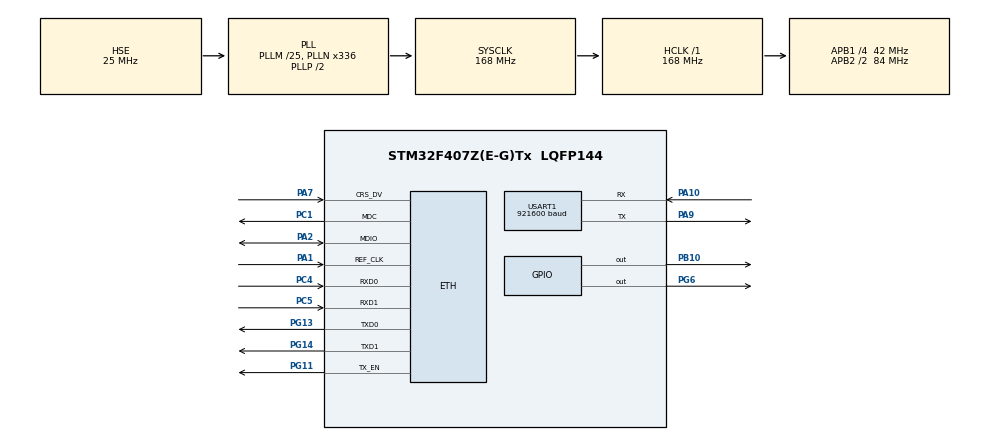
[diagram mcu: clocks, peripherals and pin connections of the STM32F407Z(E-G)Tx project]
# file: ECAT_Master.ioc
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Dma.Request0=USART1_RX
Dma.Request1=USART1_TX
Dma.USART1_RX.0.Direction=DMA_PERIPH_TO_MEMORY
Dma.USART1_RX.0.FIFOMode=DMA_FIFOMODE_DISABLE
Dma.USART1_RX.0.Instance=DMA2_Stream2
Dma.USART1_RX.0.MemDataAlignment=DMA_MDATAALIGN_BYTE
Dma.USART1_RX.0.MemInc=DMA_MINC_ENABLE
Dma.USART1_RX.0.Mode=DMA_CIRCULAR
Dma.USART1_RX.0.PeriphDataAlignment=DMA_PDATAALIGN_BYTE
Dma.USART1_RX.0.PeriphInc=DMA_PINC_DISABLE
Dma.USART1_RX.0.Priority=DMA_PRIORITY_LOW
Dma.USART1_TX.1.Direction=DMA_MEMORY_TO_PERIPH
Dma.USART1_TX.1.FIFOMode=DMA_FIFOMODE_DISABLE
Dma.USART1_TX.1.Instance=DMA2_Stream7
Dma.USART1_TX.1.MemDataAlignment=DMA_MDATAALIGN_BYTE
Dma.USART1_TX.1.MemInc=DMA_MINC_ENABLE
Dma.USART1_TX.1.Mode=DMA_NORMAL
Dma.USART1_TX.1.PeriphDataAlignment=DMA_PDATAALIGN_BYTE
Dma.USART1_TX.1.PeriphInc=DMA_PINC_DISABLE
Dma.USART1_TX.1.Priority=DMA_PRIORITY_LOW
ETH.MediaInterface=HAL_ETH_RMII_MODE
ETH.PHY_Name_RMII=LAN8742A_PHY_ADDRESS
Mcu.Family=STM32F4
Mcu.Name=STM32F407Z(E-G)Tx
Mcu.Package=LQFP144
NVIC.DMA2_Stream2_IRQn=true\:2\:0\:true\:false\:true\:false\:true\:true
NVIC.DMA2_Stream7_IRQn=true\:2\:0\:true\:false\:true\:false\:true\:true
NVIC.PriorityGroup=NVIC_PRIORITYGROUP_4
NVIC.USART1_IRQn=true\:0\:0\:false\:false\:true\:true\:true\:true
PA1.Mode=RMII
PA1.Signal=ETH_REF_CLK
PA10.Mode=Asynchronous
PA10.Signal=USART1_RX
PA13.Mode=Serial_Wire
PA13.Signal=SYS_JTMS-SWDIO
PA14.Mode=Serial_Wire
PA14.Signal=SYS_JTCK-SWCLK
PA2.Mode=RMII
PA2.Signal=ETH_MDIO
PA7.Mode=RMII
PA7.Signal=ETH_CRS_DV
PA9.Mode=Asynchronous
PA9.Signal=USART1_TX
PB10.Signal=GPIO_Output
PC1.Mode=RMII
PC1.Signal=ETH_MDC
PC4.Mode=RMII
PC4.Signal=ETH_RXD0
PC5.Mode=RMII
PC5.Signal=ETH_RXD1
PG11.Mode=RMII
PG11.Signal=ETH_TX_EN
PG13.Mode=RMII
PG13.Signal=ETH_TXD0
PG14.Mode=RMII
PG14.Signal=ETH_TXD1
PG6.Signal=GPIO_Output
PH0-OSC_IN.Mode=HSE-External-Oscillator
PH0-OSC_IN.Signal=RCC_OSC_IN
PH1-OSC_OUT.Mode=HSE-External-Oscillator
PH1-OSC_OUT.Signal=RCC_OSC_OUT
ProjectManager.HeapSize=0x200
ProjectManager.StackSize=0x400
ProjectManager.TargetToolchain=STM32CubeIDE
RCC.48MHZClocksFreq_Value=84000000
RCC.AHBFreq_Value=168000000
RCC.APB1CLKDivider=RCC_HCLK_DIV4
RCC.APB1Freq_Value=42000000
RCC.APB1TimFreq_Value=84000000
RCC.APB2CLKDivider=RCC_HCLK_DIV2
RCC.APB2Freq_Value=84000000
RCC.APB2TimFreq_Value=168000000
RCC.CortexFreq_Value=168000000
RCC.HCLKFreq_Value=168000000
RCC.HSE_VALUE=25000000
RCC.HSI_VALUE=16000000
RCC.LSE_VALUE=32768
RCC.PLLM=25
RCC.PLLN=336
RCC.PLLSourceVirtual=RCC_PLLSOURCE_HSE
RCC.SYSCLKFreq_VALUE=168000000
RCC.SYSCLKSource=RCC_SYSCLKSOURCE_PLLCLK
RCC.VCOOutputFreq_Value=336000000
TIM2.AutoReloadPreload=TIM_AUTORELOAD_PRELOAD_ENABLE
TIM2.Period=1000000
TIM2.Prescaler=84-1
TIM2.TIM_MasterOutputTrigger=TIM_TRGO_UPDATE
TIM2.TIM_MasterSlaveMode=TIM_MASTERSLAVEMODE_ENABLE
USART1.BaudRate=921600
USART1.VirtualMode=VM_ASYNC
VP_TIM2_VS_ClockSourceINT.Mode=Internal
VP_TIM5_VS_ClockSourceITR.Mode=TriggerSource_ITR0
VP_TIM5_VS_ControllerModeClock.Mode=Clock Mode
board=custom

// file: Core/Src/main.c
/* USER CODE BEGIN Header */
/**
  ******************************************************************************
  * @file           : main.c
  * @brief          : Main program body
  ******************************************************************************
  * @attention
  *
  * Copyright (c) 2023 STMicroelectronics.
  * All rights reserved.
  *
  * This software is licensed under terms that can be found in the LICENSE file
  * in the root directory of this software component.
  * If no LICENSE file comes with this software, it is provided AS-IS.
  *
  ******************************************************************************
  */
/* USER CODE END Header */
#include "main.h"
#include "dma.h"
#include "eth.h"
#include "tim.h"
#include "usart.h"
#include "gpio.h"

/* USER CODE BEGIN PTD */
void SystemClock_PreConfig(void);
/* USER CODE END PTD */

void SystemClock_Config(void);

int main(void)
{

  /* MCU Configuration--------------------------------------------------------*/

  /* Reset of all peripherals, Initializes the Flash interface and the Systick. */
  HAL_Init();

  /* USER CODE BEGIN Init */
    SystemClock_PreConfig();
  /* USER CODE END Init */

  /* Configure the system clock */
  SystemClock_Config();

  /* Initialize all configured peripherals */
  MX_GPIO_Init();
    MX_DMA_Init();
  MX_USART1_UART_Init();

  MX_ETH_Init();
  MX_TIM2_Init();
  MX_TIM5_Init();

  /* Infinite loop */
  /* USER CODE BEGIN WHILE */
  mymain();
  while (1)
  {
    /* USER CODE END WHILE */

  }
}

void SystemClock_Config(void)
{
  RCC_OscInitTypeDef RCC_OscInitStruct = {0};
  RCC_ClkInitTypeDef RCC_ClkInitStruct = {0};

  /** Configure the main internal regulator output voltage
  */
  __HAL_RCC_PWR_CLK_ENABLE();
  __HAL_PWR_VOLTAGESCALING_CONFIG(PWR_REGULATOR_VOLTAGE_SCALE1);

  /** Initializes the RCC Oscillators according to the specified parameters
  * in the RCC_OscInitTypeDef structure.
  */
  RCC_OscInitStruct.OscillatorType = RCC_OSCILLATORTYPE_HSE;
  RCC_OscInitStruct.HSEState = RCC_HSE_ON;
  RCC_OscInitStruct.PLL.PLLState = RCC_PLL_ON;
  RCC_OscInitStruct.PLL.PLLSource = RCC_PLLSOURCE_HSE;
  RCC_OscInitStruct.PLL.PLLM = 25;
  RCC_OscInitStruct.PLL.PLLN = 336;
  RCC_OscInitStruct.PLL.PLLP = RCC_PLLP_DIV2;
  RCC_OscInitStruct.PLL.PLLQ = 4;
  if (HAL_RCC_OscConfig(&RCC_OscInitStruct) != HAL_OK)
  {
    Error_Handler();
  }

  /** Initializes the CPU, AHB and APB buses clocks
  */
  RCC_ClkInitStruct.ClockType = RCC_CLOCKTYPE_HCLK|RCC_CLOCKTYPE_SYSCLK
                              |RCC_CLOCKTYPE_PCLK1|RCC_CLOCKTYPE_PCLK2;
  RCC_ClkInitStruct.SYSCLKSource = RCC_SYSCLKSOURCE_PLLCLK;
  RCC_ClkInitStruct.AHBCLKDivider = RCC_SYSCLK_DIV1;
  RCC_ClkInitStruct.APB1CLKDivider = RCC_HCLK_DIV4;
  RCC_ClkInitStruct.APB2CLKDivider = RCC_HCLK_DIV2;

  if (HAL_RCC_ClockConfig(&RCC_ClkInitStruct, FLASH_LATENCY_5) != HAL_OK)
  {
    Error_Handler();
  }
}

/* USER CODE BEGIN 4 */
void SystemClock_PreConfig(void){
    RCC_ClkInitTypeDef RCC_ClkInitStruct = {0};

    RCC_ClkInitStruct.ClockType = RCC_CLOCKTYPE_SYSCLK;
    RCC_ClkInitStruct.SYSCLKSource = RCC_SYSCLKSOURCE_HSI;
    if (HAL_RCC_ClockConfig(&RCC_ClkInitStruct, FLASH_LATENCY_5) != HAL_OK)
    {
        Error_Handler();
    }
}
/* USER CODE END 4 */

void Error_Handler(void)
{
  __disable_irq();
  while (1)
  {
  }
}
